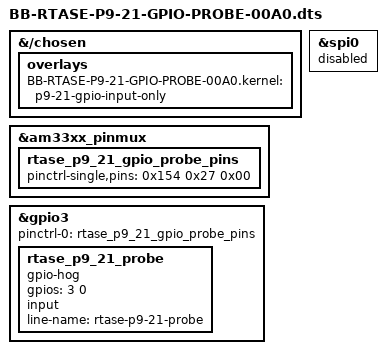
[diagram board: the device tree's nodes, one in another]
/* Diagnostic-only: route BBB P9_21 / U2 pin 33 return net to GPIO3_3 input.
 * SPI0 is disabled so no peripheral claims the pin.  This overlay never
 * drives P9_21; it holds it as an input via a GPIO hog. */
/dts-v1/;
/plugin/;

&{/chosen} {
	overlays {
		BB-RTASE-P9-21-GPIO-PROBE-00A0.kernel = "p9-21-gpio-input-only";
	};
};

&am33xx_pinmux {
	rtase_p9_21_gpio_probe_pins: rtase_p9_21_gpio_probe_pins {
		pinctrl-single,pins = <
			0x154 0x27 0x00  /* P9_21 -> GPIO3_3 input, receiver enabled */
		>;
	};
};

&spi0 {
	status = "disabled";
};

&gpio3 {
	status = "okay";
	pinctrl-names = "default";
	pinctrl-0 = <&rtase_p9_21_gpio_probe_pins>;
	rtase_p9_21_probe {
		gpio-hog;
		gpios = <3 0>;
		input;
		line-name = "rtase-p9-21-probe";
	};
};
